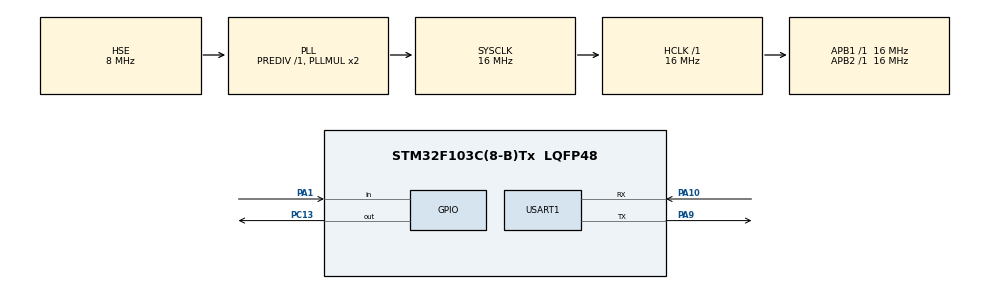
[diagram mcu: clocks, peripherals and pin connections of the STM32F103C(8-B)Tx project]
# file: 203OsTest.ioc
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FREERTOS.Tasks01=defaultTask,24,128,StartDefaultTask,Default,NULL,Dynamic,NULL,NULL;myTask02,8,128,StartTask02,Default,NULL,Dynamic,NULL,NULL;myTask03,8,128,StartTask03,Default,NULL,Dynamic,NULL,NULL;myTask04,8,128,StartTask04,Default,NULL,Dynamic,NULL,NULL
Mcu.Family=STM32F1
Mcu.Name=STM32F103C(8-B)Tx
Mcu.Package=LQFP48
NVIC.PriorityGroup=NVIC_PRIORITYGROUP_4
NVIC.TIM1_UP_IRQn=true\:5\:0\:false\:false\:true\:true\:true\:true\:true
PA1.GPIO_PuPd=GPIO_PULLUP
PA1.Signal=GPIO_Input
PA10.Mode=Asynchronous
PA10.Signal=USART1_RX
PA13.Mode=Serial_Wire
PA13.Signal=SYS_JTMS-SWDIO
PA14.Mode=Serial_Wire
PA14.Signal=SYS_JTCK-SWCLK
PA9.Mode=Asynchronous
PA9.Signal=USART1_TX
PC13-TAMPER-RTC.Signal=GPIO_Output
PD0-OSC_IN.Mode=HSE-External-Oscillator
PD0-OSC_IN.Signal=RCC_OSC_IN
PD1-OSC_OUT.Mode=HSE-External-Oscillator
PD1-OSC_OUT.Signal=RCC_OSC_OUT
ProjectManager.HeapSize=0x200
ProjectManager.StackSize=0x400
ProjectManager.TargetToolchain=MDK-ARM V5.32
RCC.AHBFreq_Value=16000000
RCC.APB1Freq_Value=16000000
RCC.APB1TimFreq_Value=16000000
RCC.APB2Freq_Value=16000000
RCC.APB2TimFreq_Value=16000000
RCC.HCLKFreq_Value=16000000
RCC.PLLSourceVirtual=RCC_PLLSOURCE_HSE
RCC.SYSCLKFreq_VALUE=16000000
RCC.SYSCLKSource=RCC_SYSCLKSOURCE_PLLCLK
RCC.USBFreq_Value=16000000
TIM1.Period=7199
TIM1.Prescaler=9
USART1.VirtualMode=VM_ASYNC
VP_FREERTOS_VS_CMSIS_V2.Mode=CMSIS_V2
VP_TIM1_VS_ClockSourceINT.Mode=Internal
board=custom

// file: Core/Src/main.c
/* USER CODE BEGIN Header */
/**
  ******************************************************************************
  * @file           : main.c
  * @brief          : Main program body
  ******************************************************************************
  * @attention
  *
  * Copyright (c) 2026 STMicroelectronics.
  * All rights reserved.
  *
  * This software is licensed under terms that can be found in the LICENSE file
  * in the root directory of this software component.
  * If no LICENSE file comes with this software, it is provided AS-IS.
  *
  ******************************************************************************
  */
/* USER CODE END Header */
#include "main.h"
#include "cmsis_os.h"

/* USER CODE BEGIN Includes */
#include "user_task.h"
/* USER CODE END Includes */

TIM_HandleTypeDef htim1;

UART_HandleTypeDef huart1;

/* Definitions for defaultTask */
osThreadId_t defaultTaskHandle;
const osThreadAttr_t defaultTask_attributes = {
  .name = "defaultTask",
  .stack_size = 128 * 4,
  .priority = (osPriority_t) osPriorityNormal,
};
/* Definitions for myTask02 */
osThreadId_t myTask02Handle;
const osThreadAttr_t myTask02_attributes = {
  .name = "myTask02",
  .stack_size = 128 * 4,
  .priority = (osPriority_t) osPriorityLow,
};
/* Definitions for myTask03 */
osThreadId_t myTask03Handle;
const osThreadAttr_t myTask03_attributes = {
  .name = "myTask03",
  .stack_size = 128 * 4,
  .priority = (osPriority_t) osPriorityLow,
};
/* Definitions for myTask04 */
osThreadId_t myTask04Handle;
const osThreadAttr_t myTask04_attributes = {
  .name = "myTask04",
  .stack_size = 128 * 4,
  .priority = (osPriority_t) osPriorityLow,
};

void SystemClock_Config(void);
static void MX_GPIO_Init(void);
static void MX_USART1_UART_Init(void);
static void MX_TIM1_Init(void);
void StartDefaultTask(void *argument);
void StartTask02(void *argument);
void StartTask03(void *argument);
void StartTask04(void *argument);

int main(void)
{

  /* MCU Configuration--------------------------------------------------------*/

  /* Reset of all peripherals, Initializes the Flash interface and the Systick. */
  HAL_Init();

  /* Configure the system clock */
  SystemClock_Config();

  /* Initialize all configured peripherals */
  MX_GPIO_Init();
  MX_USART1_UART_Init();
  MX_TIM1_Init();

  /* Init scheduler */
  osKernelInitialize();

  /* Create the thread(s) */
  /* creation of defaultTask */
  defaultTaskHandle = osThreadNew(StartDefaultTask, NULL, &defaultTask_attributes);

  /* creation of myTask02 */
  myTask02Handle = osThreadNew(StartTask02, NULL, &myTask02_attributes);

  /* creation of myTask03 */
  myTask03Handle = osThreadNew(StartTask03, NULL, &myTask03_attributes);

  /* creation of myTask04 */
  myTask04Handle = osThreadNew(StartTask04, NULL, &myTask04_attributes);

  /* Start scheduler */
  osKernelStart();

  /* We should never get here as control is now taken by the scheduler */

  /* Infinite loop */
  while (1)
  {

  }
}

void SystemClock_Config(void)
{
  RCC_OscInitTypeDef RCC_OscInitStruct = {0};
  RCC_ClkInitTypeDef RCC_ClkInitStruct = {0};

  /** Initializes the RCC Oscillators according to the specified parameters
  * in the RCC_OscInitTypeDef structure.
  */
  RCC_OscInitStruct.OscillatorType = RCC_OSCILLATORTYPE_HSE;
  RCC_OscInitStruct.HSEState = RCC_HSE_ON;
  RCC_OscInitStruct.HSEPredivValue = RCC_HSE_PREDIV_DIV1;
  RCC_OscInitStruct.HSIState = RCC_HSI_ON;
  RCC_OscInitStruct.PLL.PLLState = RCC_PLL_ON;
  RCC_OscInitStruct.PLL.PLLSource = RCC_PLLSOURCE_HSE;
  RCC_OscInitStruct.PLL.PLLMUL = RCC_PLL_MUL2;
  if (HAL_RCC_OscConfig(&RCC_OscInitStruct) != HAL_OK)
  {
    Error_Handler();
  }

  /** Initializes the CPU, AHB and APB buses clocks
  */
  RCC_ClkInitStruct.ClockType = RCC_CLOCKTYPE_HCLK|RCC_CLOCKTYPE_SYSCLK
                              |RCC_CLOCKTYPE_PCLK1|RCC_CLOCKTYPE_PCLK2;
  RCC_ClkInitStruct.SYSCLKSource = RCC_SYSCLKSOURCE_PLLCLK;
  RCC_ClkInitStruct.AHBCLKDivider = RCC_SYSCLK_DIV1;
  RCC_ClkInitStruct.APB1CLKDivider = RCC_HCLK_DIV1;
  RCC_ClkInitStruct.APB2CLKDivider = RCC_HCLK_DIV1;

  if (HAL_RCC_ClockConfig(&RCC_ClkInitStruct, FLASH_LATENCY_0) != HAL_OK)
  {
    Error_Handler();
  }
}

static void MX_TIM1_Init(void)
{

  TIM_ClockConfigTypeDef sClockSourceConfig = {0};
  TIM_MasterConfigTypeDef sMasterConfig = {0};

  htim1.Instance = TIM1;
  htim1.Init.Prescaler = 9;
  htim1.Init.CounterMode = TIM_COUNTERMODE_UP;
  htim1.Init.Period = 7199;
  htim1.Init.ClockDivision = TIM_CLOCKDIVISION_DIV1;
  htim1.Init.RepetitionCounter = 0;
  htim1.Init.AutoReloadPreload = TIM_AUTORELOAD_PRELOAD_DISABLE;
  if (HAL_TIM_Base_Init(&htim1) != HAL_OK)
  {
    Error_Handler();
  }
  sClockSourceConfig.ClockSource = TIM_CLOCKSOURCE_INTERNAL;
  if (HAL_TIM_ConfigClockSource(&htim1, &sClockSourceConfig) != HAL_OK)
  {
    Error_Handler();
  }
  sMasterConfig.MasterOutputTrigger = TIM_TRGO_RESET;
  sMasterConfig.MasterSlaveMode = TIM_MASTERSLAVEMODE_DISABLE;
  if (HAL_TIMEx_MasterConfigSynchronization(&htim1, &sMasterConfig) != HAL_OK)
  {
    Error_Handler();
  }
  /* USER CODE BEGIN TIM1_Init 2 */
  __HAL_TIM_ENABLE_IT(&htim1, TIM_IT_UPDATE);
  HAL_TIM_Base_Start(&htim1);
  /* USER CODE END TIM1_Init 2 */

}

static void MX_USART1_UART_Init(void)
{

  huart1.Instance = USART1;
  huart1.Init.BaudRate = 115200;
  huart1.Init.WordLength = UART_WORDLENGTH_8B;
  huart1.Init.StopBits = UART_STOPBITS_1;
  huart1.Init.Parity = UART_PARITY_NONE;
  huart1.Init.Mode = UART_MODE_TX_RX;
  huart1.Init.HwFlowCtl = UART_HWCONTROL_NONE;
  huart1.Init.OverSampling = UART_OVERSAMPLING_16;
  if (HAL_UART_Init(&huart1) != HAL_OK)
  {
    Error_Handler();
  }

}

static void MX_GPIO_Init(void)
{
  GPIO_InitTypeDef GPIO_InitStruct = {0};

  /* GPIO Ports Clock Enable */
  __HAL_RCC_GPIOC_CLK_ENABLE();
  __HAL_RCC_GPIOD_CLK_ENABLE();
  __HAL_RCC_GPIOA_CLK_ENABLE();

  /*Configure GPIO pin Output Level */
  HAL_GPIO_WritePin(GPIOC, GPIO_PIN_13, GPIO_PIN_RESET);

  /*Configure GPIO pin : PC13 */
  GPIO_InitStruct.Pin = GPIO_PIN_13;
  GPIO_InitStruct.Mode = GPIO_MODE_OUTPUT_PP;
  GPIO_InitStruct.Pull = GPIO_NOPULL;
  GPIO_InitStruct.Speed = GPIO_SPEED_FREQ_LOW;
  HAL_GPIO_Init(GPIOC, &GPIO_InitStruct);

  /*Configure GPIO pin : PA1 */
  GPIO_InitStruct.Pin = GPIO_PIN_1;
  GPIO_InitStruct.Mode = GPIO_MODE_INPUT;
  GPIO_InitStruct.Pull = GPIO_PULLUP;
  HAL_GPIO_Init(GPIOA, &GPIO_InitStruct);

}

void StartDefaultTask(void *argument)
{
  for(;;)
  {
    osDelay(1);
  }
}

void StartTask02(void *argument)
{
  /* USER CODE BEGIN StartTask02 */
  /* Infinite loop */
  for(;;)
  {
    vButtonTask();
  }
  /* USER CODE END StartTask02 */
}

void StartTask03(void *argument)
{
  /* USER CODE BEGIN StartTask03 */
  /* Infinite loop */
  for(;;)
  {
    vUartTask();
  }
  /* USER CODE END StartTask03 */
}

void StartTask04(void *argument)
{
  /* USER CODE BEGIN StartTask04 */
  /* Infinite loop */
  for(;;)
  {
    vAdcTask();
  }
  /* USER CODE END StartTask04 */
}

void Error_Handler(void)
{
  __disable_irq();
  while (1)
  {
  }
}
